# nrf7140_secure register map
Vendor: Nordic Semiconductor; Series: nRF71; File version: 1
CPU: CM33 r0p4, little endian, MPU, no FPU, 3 interrupt priority bits, 480 interrupts, 8 SAU regions
Registers are 32-bit, read-write, reset 0x0 unless marked. A register's access mark holds for its fields unless they carry their own. Offsets are from the block's base; [hi:lo] are bit positions; lines under a group give offsets from that group; {n}, {i} and the like mark numbered series.

## CPUCONF_NS — CPU Configuration 0
Base 0x41011000
Same registers: CPUCONF_S 0x51011000
0x00 TASKS_ERASECACHE wo — Erase the caches used by the CPU.
  [0] TASKS_ERASECACHE
    1=Trigger task
0x500 INITSVTOR reset 0x1000000 — Initial value of the secure VTOR (Vector Table Offset Register) after CPU reset.
  [31:0] INITSVTOR — Initial value of the VTOR.
0x504 INITNSVTOR reset 0x1000000 — Initial value of the non-secure VTOR (Vector Table Offset Register).
  [31:0] INITNSVTOR — Initial value of the VTOR.
0x508 CPUSTART reset 0x1 — Enable for starting the CPU
  [0] EN — Enable to start the CPU.
    0=Stopped (CPU stopped.); 1=Started (CPU started.)
0x50C CPUWAIT — Enable for the CPU wait.
  [0] EN — Enable to the CPU wait.
    0=Disabled (CPU is not waiting.); 1=Enabled (CPU is waiting.)

## MUTEX_NS — MUTEX 0
Base 0x41017000
Same registers: MUTEX_S 0x51017000
{0x400+4i} MUTEX[{i}] (i=0..7) — Description collection: Mutex register
  [0] MUTEX — Mutex register n
    0=Unlocked (Mutex n is in unlocked state); 1=Locked (Mutex n is in locked state)

## RESETINFO_S — RESETINFO
Base 0x5101E000; alternate view of LRCCONF010_NS
0x4A0 RESETREAS group — Unspecified
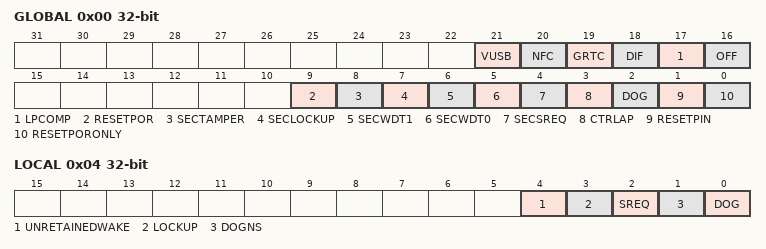
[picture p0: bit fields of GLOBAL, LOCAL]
  0x00 GLOBAL — Global reset reason.
    [all] fields
      0=NotDetected; 1=Detected
    [21] VUSB — Reset after wakeup from System OFF mode due to VBUS rising into valid range.
    [20] NFC — Reset due to wakeup from System OFF mode when wakeup is triggered by NFC field detection in sense mode.
    [19] GRTC — Reset due to wakeup from System OFF mode when wakeup is triggered by GRTC interrupt.
    [18] DIF — Reset due to wakeup from System OFF mode when wakeup is triggered by entering the debug interface mode.
    [17] LPCOMP — Reset due to wakeup from System OFF mode when wakeup is triggered by LPCOMP (Low Power Comparator).
    [16] OFF — Reset due to wakeup from System OFF mode when wakeup is triggered by DETECT signal from GPIO.
    [9] RESETPOR — Reset from power on reset (reset reason other than POR or BOR).
    [8] SECTAMPER — Reset due to secure domain tamper detected
    [7] SECLOCKUP — Reset due to secure domain lockup.
    [6] SECWDT1 — Reset due to the second instance of watchdog timer in secure domain detected.
    [5] SECWDT0 — Reset due to the first instance of watchdog timer in secure domain detected.
    [4] SECSREQ — Reset due to secure domain system reset request.
    [3] CTRLAP — Reset from CTRL-AP detected.
    [2] DOG — Reset from the SysCtrl watchdog timer detected.
    [1] RESETPIN — Reset from pin reset detected.
    [0] RESETPORONLY — Reset from power on reset (reset reason POR or BOR).
  0x04 LOCAL — Local reset reason.
    [4] UNRETAINEDWAKE — Reset due to wake from unretained state.
    [3] LOCKUP — Reset from local CPU lockup detected
      0=NotDetected; 1=Detected
    [2] SREQ — Reset from the local soft reset request detected.
      0=NotDetected; 1=Detected
    [1] DOGNS — Reset from the local non-secure watchdog timer detected
      0=NotDetected; 1=Detected
    [0] DOG — Reset from the local watchdog timer detected
      0=NotDetected; 1=Detected
0x4A8 ERROR group — Unspecified
  0x00 STATUS — Reset error status.
    [3:0] ERRORSTATUS
  0x04 ADDRESS — Reset error address.
    [31:0] ERRORADDRESS
0x4C0 RESTOREVALID — Valid restore image is present in RAM.
  [0] RESTOREVALID
    0=NotPreset (Not present); 1=Present
0x4C4 MASKLOCKUP — Mask CPU lockup signal.
  [0] MASK — Mask lockup signal
    0=NotMask (Do not mask lockup signal); 1=Mask lockup signal

## SWI0_NS — Software interrupt 0
Base 0x42058000
Same registers: SWI1_NS 0x42059000, SWI2_NS 0x4205A000, SWI3_NS 0x4205B000, SWI4_NS 0x4205C000, SWI5_NS 0x4205D000, SWI6_NS 0x4205E000, SWI7_NS 0x4205F000
